# neorv32 register map
Vendor: github.com/stnolting/neorv32; Series: RISC-V; File version: 1.12.8
The NEORV32 RISC-V Processor
CPU: other r1p0, little endian, MPU, FPU, I-cache, D-cache, ITCM, DTCM, 4 interrupt priority bits
Address unit: 16 bits
Registers are 32-bit, read-write, reset 0x0 unless marked. A register's access mark holds for its fields unless they carry their own. Offsets are from the block's base; lines under a group give offsets from that group; [hi:lo] are bit positions; {n}, {i} and the like mark numbered series; 'fields as' and 'values as' point back to an identical list; <NAME> marks a mode.

## Memory map
0xFFEA0000 TWD size 0x8 — Two-wire device controller
0xFFEB0000 CFS size 0x10000 — Custom functions subsystem
0xFFEC0000 SLINK size 0x10 — Stream Link Interface
0xFFED0000 DMA size 0x10 — Direct memory access controller
0xFFF00000 PWM size 0x100 — Pulse-width modulation controller
0xFFF10000 GPTMR size 0x100 — General purpose timer
0xFFF20000 ONEWIRE size 0x8 — 1-Wire Interface Controller
0xFFF30000 TRACER size 0x10 — Execution Trace Buffer
0xFFF40000 CLINT size 0x10000 — Core local interruptor
0xFFF50000 UART0 size 0x8 — Primary universal asynchronous receiver and transmitter
0xFFF60000 UART1 size 0x8 — Secondary universal asynchronous receiver and transmitter
0xFFF70000 SDI size 0x8 — Serial data interface controller
0xFFF80000 SPI size 0x8 — Serial peripheral interface controller
0xFFF90000 TWI size 0x8 — Two-wire interface controller
0xFFFA0000 TRNG size 0x8 — True random number generator
0xFFFB0000 WDT size 0x8 — Watchdog timer
0xFFFC0000 GPIO size 0x20 — General purpose input/output port
0xFFFD0000 NEOLED size 0x10 — Smart LED hardware interface
0xFFFE0000 SYSINFO size 0x10 — System configuration information memory

## Interrupts
0 TWD_FIRQ (TWD)
1 CFS_FIRQ (CFS)
2 UART0_FIRQ (UART0)
3 UART1_FIRQ (UART1)
5 TRACER_FIRQ (TRACER)
6 SPI_FIRQ (SPI)
7 TWI_FIRQ (TWI)
8 GPIO_FIRQ (GPIO)
9 NEOLED_FIRQ (NEOLED)
10 DMA_FIRQ (DMA)
11 SDI_FIRQ (SDI)
12 GPTMR_FIRQ (GPTMR)
13 ONEWIRE_FIRQ (ONEWIRE)
14 SLINK_FIRQ (SLINK)
15 TRNG_FIRQ (TRNG)

## CFS — Custom functions subsystem
Base 0xFFEB0000
{0x0+4i} REG{i} (i=0..63) — User-defined

## SDI — Serial data interface controller
Base 0xFFF70000
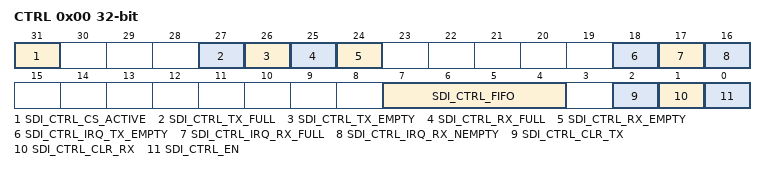
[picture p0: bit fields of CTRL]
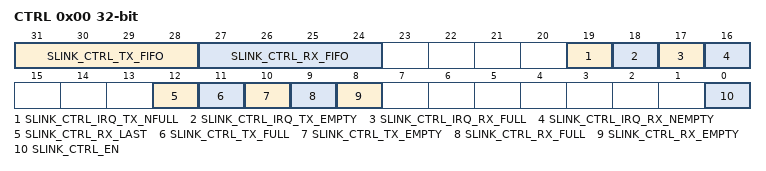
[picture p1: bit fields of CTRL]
0x00 CTRL — Control register
  [31] SDI_CTRL_CS_ACTIVE ro — Chip-select line is active when set
  [27] SDI_CTRL_TX_FULL ro — TX FIFO full
  [26] SDI_CTRL_TX_EMPTY ro — TX FIFO empty
  [25] SDI_CTRL_RX_FULL ro — RX FIFO full
  [24] SDI_CTRL_RX_EMPTY ro — RX FIFO empty
  [18] SDI_CTRL_IRQ_TX_EMPTY — Fire interrupt if TX FIFO is empty
  [17] SDI_CTRL_IRQ_RX_FULL — Fire interrupt if RX FIFO is full
  [16] SDI_CTRL_IRQ_RX_NEMPTY — Fire interrupt if RX FIFO is not empty
  [7:4] SDI_CTRL_FIFO — log2(FIFO size)
  [2] SDI_CTRL_CLR_TX wo — Clear TX FIFO, flag auto-clears
  [1] SDI_CTRL_CLR_RX wo — Clear RX FIFO, flag auto-clears
  [0] SDI_CTRL_EN — SDI enable
0x04 DATA read-modifies — RX/TX data register
  [7:0] SDI_DATA — RX data / TX data (via FIFOs)

## SLINK — Stream Link Interface
Base 0xFFEC0000
0x00 CTRL — Control register
  [31:28] SLINK_CTRL_TX_FIFO ro — log2(TX FIFO size)
  [27:24] SLINK_CTRL_RX_FIFO ro — log2(RX FIFO size)
  [19] SLINK_CTRL_IRQ_TX_NFULL — Interrupt if TX FIFO not full
  [18] SLINK_CTRL_IRQ_TX_EMPTY — Interrupt if TX FIFO empty
  [17] SLINK_CTRL_IRQ_RX_FULL — Interrupt if RX FIFO full
  [16] SLINK_CTRL_IRQ_RX_NEMPTY — Interrupt if RX FIFO not empty
  [12] SLINK_CTRL_RX_LAST — RX link end-of-stream delimiter
  [11] SLINK_CTRL_TX_FULL ro — TX FIFO full
  [10] SLINK_CTRL_TX_EMPTY ro — TX FIFO empty
  [9] SLINK_CTRL_RX_FULL ro — RX FIFO full
  [8] SLINK_CTRL_RX_EMPTY ro — RX FIFO empty
  [0] SLINK_CTRL_EN — SLINK enable flag
0x04 ROUTE — Routing information
  [3:0] SLINK_ROUTE — RX/TX stream source/destination address/ID
0x08 DATA read-modifies — RX/TX data register
0x0C DATA_LAST read-modifies — TX data register (plus TX end-of-stream delimiter)

## DMA — Direct memory access controller
Base 0xFFED0000
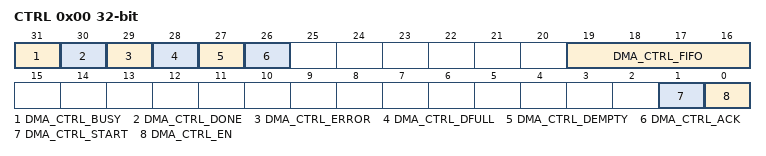
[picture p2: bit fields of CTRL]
0x00 CTRL — Control and status register
  [31] DMA_CTRL_BUSY ro — Transfer(s) in progress
  [30] DMA_CTRL_DONE ro — Transfer(s) done
  [29] DMA_CTRL_ERROR ro — Error during last transfer
  [28] DMA_CTRL_DFULL ro — Descriptor FIFO is full
  [27] DMA_CTRL_DEMPTY ro — Descriptor FIFO is empty
  [26] DMA_CTRL_ACK wo — Write 1 to clear ERROR and DONE flags
  [19:16] DMA_CTRL_FIFO ro — log2(descriptor FIFO depth)
  [1] DMA_CTRL_START wo — Start programmed DMA transfer(s)
  [0] DMA_CTRL_EN — DMA enable flag
0x04 DESC wo — Descriptor FIFO
